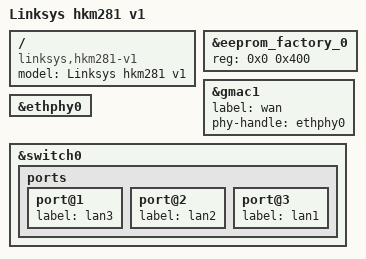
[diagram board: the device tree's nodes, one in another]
// SPDX-License-Identifier: GPL-2.0-or-later OR MIT

#include "mt7621_linksys_ea7xxx.dtsi"

/ {
	compatible = "linksys,hkm281-v1", "mediatek,mt7621-soc";
	model = "Linksys hkm281 v1";
};

/* override EEPROM size to 0x400 for MT7603 */
&eeprom_factory_0 {
	reg = <0x0 0x400>;
};

&gmac1 {
	status = "okay";
	label = "wan";
	phy-handle = <&ethphy0>;
};

&ethphy0 {
	/delete-property/ interrupts;
};

&switch0 {
	ports {
		port@1 {
			status = "okay";
			label = "lan3";
		};

		port@2 {
			status = "okay";
			label = "lan2";
		};

		port@3 {
			status = "okay";
			label = "lan1";
		};
	};
};
